# ADSP-2183xW_HPC register map
Vendor: Analog Devices; Series: ADSP-2183xW_HPC; File version: 3.0.3.517
CPU: 
Registers are 32-bit, read-write, reset 0x0 unless marked. A register's access mark holds for its fields unless they carry their own. Offsets are from the block's base; [hi:lo] are bit positions; {n}, {i} and the like mark numbered series; 'fields as' and 'values as' point back to an identical list; <NAME> marks a mode.

## DMA0 — The Direct Memory Access module
Base 0x31022000
Same registers: DMA30 0x30FFF000, DMA36 0x30FFF080, DMA1 0x31022080, DMA2 0x31022100, DMA3 0x31022180, DMA4 0x31022200, DMA5 0x31022280, DMA6 0x31022300, DMA7 0x31022380, DMA{n} {0x31022B00+0x80*n} (n=10..17), DMA21 0x31026000, DMA20 0x31026080, DMA35 0x31026100, DMA34 0x31026180, DMA38 0x31026200, DMA37 0x31026280, DMA22 0x3102D000, DMA23 0x3102D080, DMA24 0x3102D100, DMA25 0x3102D180, DMA26 0x3102D200, DMA27 0x3102D280, DMA8 0x310A7000, DMA9 0x310A7080, DMA18 0x310A7100, DMA19 0x310A7180, DMA45 0x310A7200, DMA46 0x310A7280, DMA47 0x310A7300, DMA48 0x310A7380
0x00 DSCPTR_NXT — Pointer to Next Initial Descriptor Register
  [31:0] VALUE range 0x00000000..0xFFFFFFFF — Pointer to Next Descriptor Set
0x04 ADDRSTART — Start Address of Current Buffer Register
  [31:0] VALUE range 0x00000000..0xFFFFFFFF — Work Unit Address Start Value
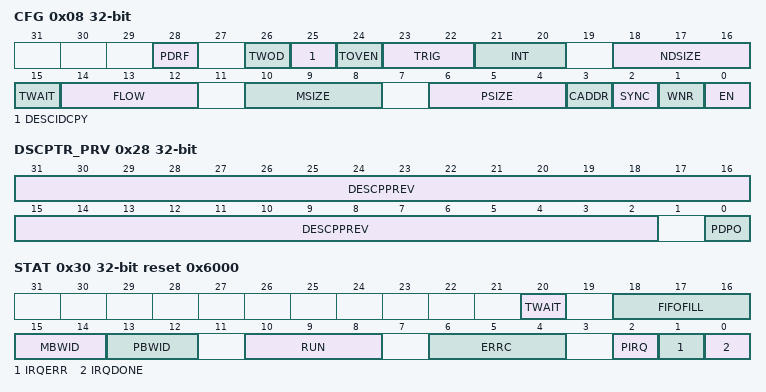
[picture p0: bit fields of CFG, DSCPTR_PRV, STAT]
0x08 CFG — Configuration Register
  [28] PDRF — Peripheral Data Request Forward
    0=PDAT_NOTFWD (Peripheral Data Request Not Forwarded); 1=PDAT_FWD (Peripheral Data Request Forwarded)
  [26] TWOD — Two Dimension Addressing Enable
    0=ADDR1D (One-Dimensional Addressing); 1=ADDR2D (Two-Dimensional Addressing)
  [25] DESCIDCPY — Descriptor ID Copy Control
    0=NO_COPY (Never Copy); 1=COPY (Copy on Work Unit Complete)
  [24] TOVEN — Trigger Overrun Error Enable
    0=TOV_DIS (Ignore Trigger Overrun); 1=TOV_EN (Error on Trigger Overrun)
  [23:22] TRIG — Generate Outgoing Trigger
    0=NO_TRIG (Never Assert Trigger); 1=XCNT_TRIG (Trigger When XCNTCUR Reaches 0); 2=YCNT_TRIG (Trigger When YCNTCUR Reaches 0)
  [21:20] INT — Generate Interrupt Request
    0=NO_INT (Never Assert Interrupt); 1=XCNT_INT (Interrupt When X Count Expires); 2=YCNT_INT (Interrupt When Y Count Expires); 3=PERIPH_INT (Peripheral Interrupt request)
  [18:16] NDSIZE — Next Descriptor Set Size
    0=FETCH01 (Fetch One Descriptor Element); 1=FETCH02 (Fetch Two Descriptor Elements); 2=FETCH03 (Fetch Three Descriptor Elements); 3=FETCH04 (Fetch Four Descriptor Elements); 4=FETCH05 (Fetch Five Descriptor Elements); 5=FETCH06 (Fetch Six Descriptor Elements); 6=FETCH07 (Fetch Seven Descriptor Elements)
  [15] TWAIT — Wait for Trigger
    0=NO_TRGWAIT (Begin Work Unit Automatically (No Wait)); 1=TRGWAIT (Wait for Trigger (Halt before Work Unit))
  [14:12] FLOW — Next Operation
    0=STOP; 1=AUTO; 4=DSCLIST; 5=DSCARRAY; 6=DODLIST (Descriptor On-Demand List.); 7=DODARRAY (Descriptor On Demand Array.)
  [10:8] MSIZE — Memory Transfer Word Size
    0=1 Byte; 1=2 Bytes; 2=4 Bytes; 3=8 Bytes; 4=16 Bytes; 5=32 Bytes
  [6:4] PSIZE — Peripheral Transfer Word Size
    0=1 Byte; 1=2 Bytes; 2=4 Bytes; 3=8 Bytes
  [3] CADDR — Use Current Address
    0=LD_STARTADDR (Load Starting Address); 1=LD_CURADDR (Use Current Address)
  [2] SYNC — Synchronize Work Unit Transitions
    0=NO_SYNC (No Synchronization); 1=SYNC (Synchronize Channel)
  [1] WNR — Write/Read Channel Direction
    0=READ (Transmit (Read from memory)); 1=WRITE (Receive (Write to memory))
  [0] EN — DMA Channel Enable
    0=DIS (Disable); 1=EN (Enable)
0x0C XCNT — Inner Loop Count Start Value Register
  [31:0] VALUE range 0x00000000..0xFFFFFFFF — Work Unit Inner Loop Counter Start Value
0x10 XMOD — Inner Loop Address Increment Register
  [31:0] VALUE range 0x00000000..0xFFFFFFFF — Inner Loop Address Increment in Bytes
0x14 YCNT — Outer Loop Count Start Value (2D only) Register
  [31:0] VALUE range 0x00000000..0xFFFFFFFF — Work Unit Inner Loop Counter Current Value
0x18 YMOD — Outer Loop Address Increment (2D only) Register
  [31:0] VALUE range 0x00000000..0xFFFFFFFF — Outer Loop Address Increment in Bytes
0x24 DSCPTR_CUR — Current Descriptor Pointer Register
  [31:0] VALUE range 0x00000000..0xFFFFFFFF — Pointer for Current Descriptor Element
0x28 DSCPTR_PRV — Previous Initial Descriptor Pointer Register
  [31:2] DESCPPREV ro — Descriptor Pointer for Previous Element
  [0] PDPO ro — Previous Descriptor Pointer Overrun
0x2C ADDR_CUR — Current Address Register
  [31:0] VALUE range 0x00000000..0xFFFFFFFF — Work Unit Current Address Value
0x30 STAT reset 0x6000 — Status Register
  [20] TWAIT ro — Trigger Wait Status
    0=NOTRIGRX (No Trigger Received); 1=TRIGRX (Trigger Received)
  [18:16] FIFOFILL ro — FIFO Fill Status
    0=FIFOEMPTY (Empty); 1=FIFO25 (Empty < FIFO = 1/4 Full); 2=FIFO50 (1/4 Full < FIFO = 1/2 Full); 3=FIFO75 (1/2 Full < FIFO = 3/4 Full); 4=FIFONEARFULL (3/4 Full < FIFO = Full); 7=FIFOFULL (Full)
  [15:14] MBWID ro — Memory Bus Width
    0=MBUS02 (2 Bytes); 1=MBUS04 (4 Bytes); 2=MBUS08 (8 Bytes); 3=MBUS16 (16 Bytes)
  [13:12] PBWID ro — Peripheral Bus Width
    0=PBUS01 (1 Byte); 1=PBUS02 (2 Bytes); 2=PBUS04 (4 Bytes); 3=PBUS08 (8 Bytes)
  [10:8] RUN ro — Run Status
    0=STOPPED (Idle/Stop State); 1=DSCFETCH (Descriptor Fetch); 2=DATAXFER (Data Transfer); 3=TRGWAIT (Waiting for Trigger); 4=ACKWAIT (Waiting for Write ACK/FIFO Drain to Peripheral)
  [6:4] ERRC ro — Error Cause
    0=CFGERR (Configuration Error); 1=ILLWRERR (Illegal Write Occurred While Channel Running); 2=ALGNERR (Address Alignment Error); 3=MEMERR (Memory Access or Fabric Error); 5=TRGOVERR (Trigger Overrun); 6=BWMONERR (Bandwidth Monitor Error)
  [2] PIRQ — Peripheral Interrupt Request
    0=NO_PIRQ (No Interrupt request); 1=PIRQ (Interrupt Request signaled by peripheral)
  [1] IRQERR — Error Interrupt Request
    0=NO_IRQERR (No Error); 1=IRQERR (Error Occurred)
  [0] IRQDONE — Work Unit/Row Done Interrupt
    0=NO_IRQ (Inactive); 1=IRQDONE (Active)
0x34 XCNT_CUR — Current Count (1D) or Intra-row XCNT (2D) Register
  [31:0] VALUE ro — Work Unit Outer Loop Counter Start Value
0x38 YCNT_CUR — Current Row Count (2D only) Register
  [31:0] VALUE ro — Work Unit Outer Loop Counter Current Value
0x40 BWLCNT — Bandwidth Limit Count Register
  [15:0] VALUE range 0x00000000..0x0000FFFF — Bandwidth Limit Count
0x44 BWLCNT_CUR — Bandwidth Limit Count Current Register
  [15:0] VALUE ro — Bandwidth Limit Count Current
0x48 BWMCNT — Bandwidth Monitor Count Register
  [31:0] VALUE range 0x00000000..0xFFFFFFFF — Bandwidth Monitor Count
0x4C BWMCNT_CUR — Bandwidth Monitor Count Current Register
  [31:0] VALUE ro — Bandwidth Monitor Count Current

## DMA39 — The Direct Memory Access module
Base 0x3109A000
Same registers: DMA49 0x310AC000
Registers as DMA0; these are added or differ:
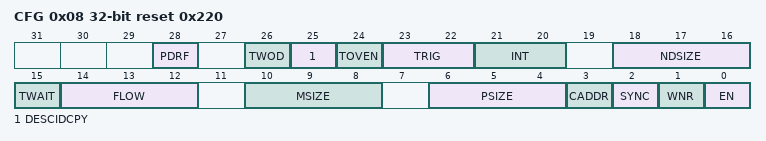
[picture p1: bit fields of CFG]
0x08 CFG reset 0x220 — Configuration Register
  [28] PDRF — Peripheral Data Request Forward
    0=PDAT_NOTFWD (Peripheral Data Request Not Forwarded); 1=PDAT_FWD (Peripheral Data Request Forwarded)
  [26] TWOD — Two Dimension Addressing Enable
    0=ADDR1D (One-Dimensional Addressing); 1=ADDR2D (Two-Dimensional Addressing)
  [25] DESCIDCPY — Descriptor ID Copy Control
    0=NO_COPY (Never Copy); 1=COPY (Copy on Work Unit Complete)
  [24] TOVEN — Trigger Overrun Error Enable
    0=TOV_DIS (Ignore Trigger Overrun); 1=TOV_EN (Error on Trigger Overrun)
  [23:22] TRIG — Generate Outgoing Trigger
    0=NO_TRIG (Never Assert Trigger); 1=XCNT_TRIG (Trigger When XCNTCUR Reaches 0); 2=YCNT_TRIG (Trigger When YCNTCUR Reaches 0)
  [21:20] INT — Generate Interrupt Request
    0=NO_INT (Never Assert Interrupt); 1=XCNT_INT (Interrupt When X Count Expires); 2=YCNT_INT (Interrupt When Y Count Expires); 3=PERIPH_INT (Peripheral Interrupt request)
  [18:16] NDSIZE — Next Descriptor Set Size
    values as DMA0.CFG.NDSIZE
  [15] TWAIT — Wait for Trigger
    0=NO_TRGWAIT (Begin Work Unit Automatically (No Wait)); 1=TRGWAIT (Wait for Trigger (Halt before Work Unit))
  [14:12] FLOW — Next Operation
    0=STOP; 1=AUTO; 4=DSCLIST; 5=DSCARRAY; 6=DODLIST (Descriptor On-Demand List.); 7=DODARRAY (Descriptor On Demand Array.)
  [10:8] MSIZE — Memory Transfer Word Size
    2=4 Bytes; 3=8 Bytes; 4=16 Bytes; 5=32 Bytes
  [6:4] PSIZE — Peripheral Transfer Word Size
    2=4 Bytes; 3=8 Bytes
  [3] CADDR — Use Current Address
    0=LD_STARTADDR (Load Starting Address); 1=LD_CURADDR (Use Current Address)
  [2] SYNC — Synchronize Work Unit Transitions
    0=NO_SYNC (No Synchronization); 1=SYNC (Synchronize Channel)
  [1] WNR ro — Write/Read Channel Direction
    0=READ (Transmit (Read from memory)); 1=WRITE (Receive (Write to memory))
  [0] EN — DMA Channel Enable
    0=DIS (Disable); 1=EN (Enable)

## DMA40 — The Direct Memory Access module
Base 0x3109A080
Same registers: DMA50 0x310AC080
Registers as DMA0; these are added or differ:
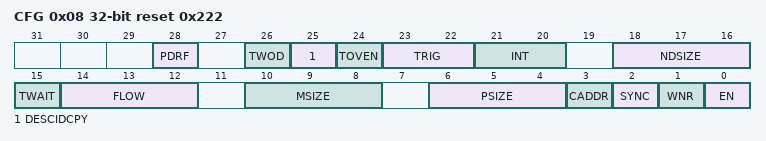
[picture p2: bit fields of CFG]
0x08 CFG reset 0x222 — Configuration Register
  fields as DMA39.CFG

## DMA43 — The Direct Memory Access module
Base 0x3109B000
Same registers: DMA51 0x3109C000
Registers as DMA39; these are added or differ:
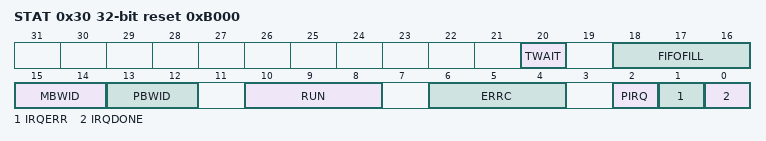
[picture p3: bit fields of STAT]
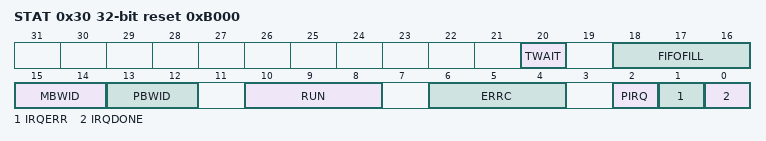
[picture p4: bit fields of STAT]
0x30 STAT reset 0xB000 — Status Register
  fields as DMA0.STAT

## DMA44 — The Direct Memory Access module
Base 0x3109B080
Same registers: DMA52 0x3109C080
Registers as DMA40; these are added or differ:
0x30 STAT reset 0xB000 — Status Register
  fields as DMA0.STAT

## Notices in the file
Copyright (c) 2018-2025 Analog Devices, Inc. All Rights Reserved.
This software is proprietary to Analog Devices, Inc. and its licensors.
